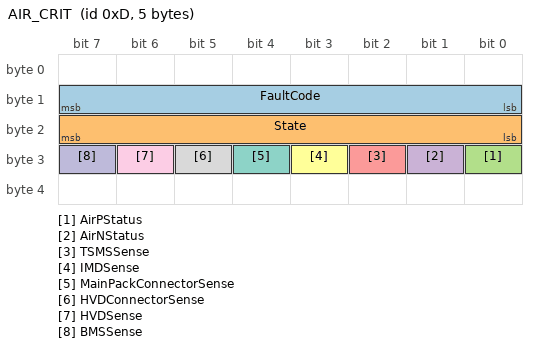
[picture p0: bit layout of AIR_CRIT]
BO_ 13 AIR_CRIT: 5 [air_control]
    SG_ FaultCode : 8|8@1+ (1,0) [0|0] "" Vector__XXX
    SG_ State : 16|8@1+ (1,0) [0|0] "" Vector__XXX
    SG_ AirPStatus : 24|1@1+ (1,0) [0|0] "" Vector__XXX
    SG_ AirNStatus : 25|1@1+ (1,0) [0|0] "" Vector__XXX
    SG_ TSMSSense : 26|1@1+ (1,0) [0|0] "" Vector__XXX
    SG_ IMDSense : 27|1@1+ (1,0) [0|0] "" Vector__XXX
    SG_ MainPackConnectorSense : 28|1@1+ (1,0) [0|0] "" Vector__XXX
    SG_ HVDConnectorSense : 29|1@1+ (1,0) [0|0] "" Vector__XXX
    SG_ HVDSense : 30|1@1+ (1,0) [0|0] "" Vector__XXX
    SG_ BMSSense : 31|1@1+ (1,0) [0|0] "" Vector__XXX

BA_ "FieldType" SG_ 13 FaultCode "AIR Fault Code";
BA_ "FieldType" SG_ 13 State "AIR State";

    0 "No Fault"
    1 "AIR_N Weld"
    2 "AIR_P Weld"
    3 "Both AIRs Welded"
    4 "Precharge Fail"
    5 "Discharge Fail"
    6 "Precharge Fail Relay Welded"
    7 "CAN BMS Timeout"
    8 "CAN Motor Controller Timeout";

    0 "Idle"
    1 "Shutdown Circuit Closed"
    2 "Precharge"
    3 "TS Active"
    4 "Discharge"
    5 "Fault";
